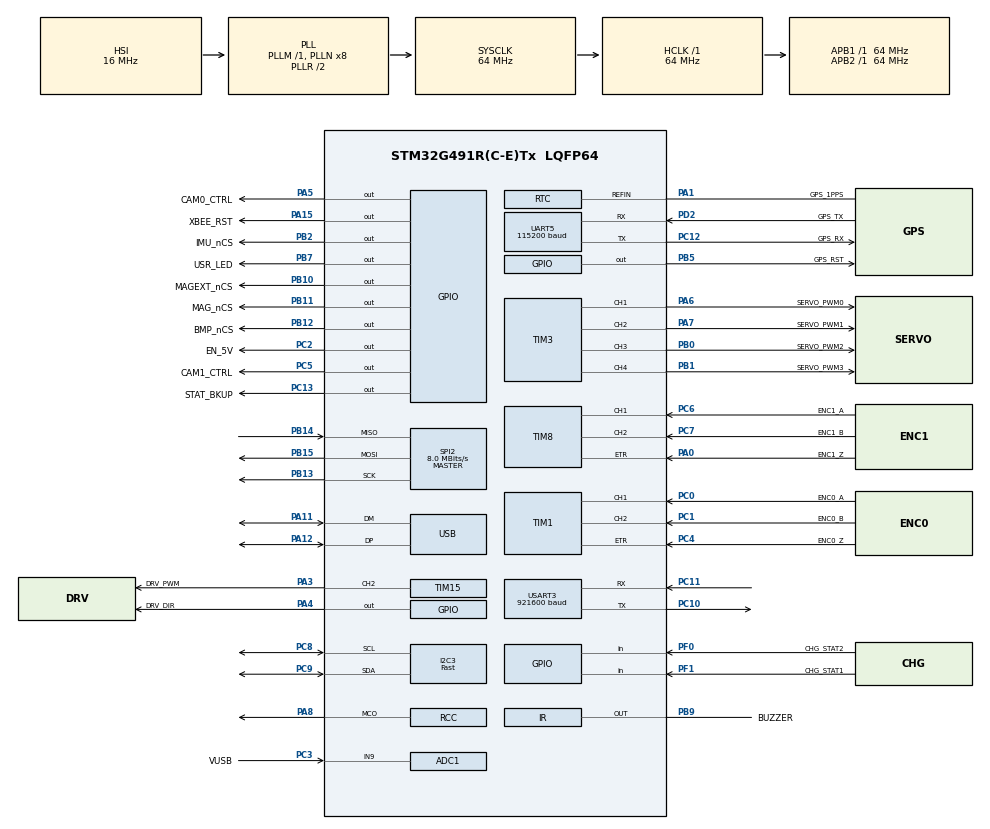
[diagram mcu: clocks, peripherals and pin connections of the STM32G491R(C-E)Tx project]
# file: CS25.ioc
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ADC1.Channel-1\#ChannelRegularConversion=ADC_CHANNEL_9
ADC1.NbrOfConversionFlag=1
ADC1.OffsetNumber-1\#ChannelRegularConversion=ADC_OFFSET_NONE
ADC1.Rank-1\#ChannelRegularConversion=1
ADC1.SamplingTime-1\#ChannelRegularConversion=ADC_SAMPLETIME_2CYCLES_5
ADC1.master=1
Dma.Request0=UART5_RX
Dma.Request1=USART3_RX
Dma.UART5_RX.0.Direction=DMA_PERIPH_TO_MEMORY
Dma.UART5_RX.0.EventEnable=DISABLE
Dma.UART5_RX.0.Instance=DMA1_Channel1
Dma.UART5_RX.0.MemDataAlignment=DMA_MDATAALIGN_BYTE
Dma.UART5_RX.0.MemInc=DMA_MINC_ENABLE
Dma.UART5_RX.0.Mode=DMA_NORMAL
Dma.UART5_RX.0.PeriphDataAlignment=DMA_PDATAALIGN_BYTE
Dma.UART5_RX.0.PeriphInc=DMA_PINC_DISABLE
Dma.UART5_RX.0.Polarity=HAL_DMAMUX_REQ_GEN_RISING
Dma.UART5_RX.0.Priority=DMA_PRIORITY_VERY_HIGH
Dma.UART5_RX.0.RequestNumber=1
Dma.UART5_RX.0.SignalID=NONE
Dma.UART5_RX.0.SyncEnable=DISABLE
Dma.UART5_RX.0.SyncPolarity=HAL_DMAMUX_SYNC_NO_EVENT
Dma.UART5_RX.0.SyncRequestNumber=1
Dma.UART5_RX.0.SyncSignalID=NONE
Dma.USART3_RX.1.Direction=DMA_PERIPH_TO_MEMORY
Dma.USART3_RX.1.EventEnable=DISABLE
Dma.USART3_RX.1.Instance=DMA1_Channel2
Dma.USART3_RX.1.MemDataAlignment=DMA_MDATAALIGN_BYTE
Dma.USART3_RX.1.MemInc=DMA_MINC_ENABLE
Dma.USART3_RX.1.Mode=DMA_NORMAL
Dma.USART3_RX.1.PeriphDataAlignment=DMA_PDATAALIGN_BYTE
Dma.USART3_RX.1.PeriphInc=DMA_PINC_DISABLE
Dma.USART3_RX.1.Polarity=HAL_DMAMUX_REQ_GEN_RISING
Dma.USART3_RX.1.Priority=DMA_PRIORITY_VERY_HIGH
Dma.USART3_RX.1.RequestNumber=1
Dma.USART3_RX.1.SignalID=NONE
Dma.USART3_RX.1.SyncEnable=DISABLE
Dma.USART3_RX.1.SyncPolarity=HAL_DMAMUX_SYNC_NO_EVENT
Dma.USART3_RX.1.SyncRequestNumber=1
Dma.USART3_RX.1.SyncSignalID=NONE
FREERTOS.BinarySemaphores01=globalData,Dynamic,NULL,Available
FREERTOS.Tasks01=readSensors,0,512,StartReadSensors,Default,NULL,Dynamic,NULL,NULL;sendTelemetry,0,512,StartSendTelemetry,Default,NULL,Dynamic,NULL,NULL;readCommands,0,512,StartReadCommands,Default,NULL,Dynamic,NULL,NULL;guideNavCtrl,0,512,StartGNC,Default,NULL,Dynamic,NULL,NULL
FREERTOS.configIDLE_SHOULD_YIELD=1
FREERTOS.configMINIMAL_STACK_SIZE=512
FREERTOS.configTOTAL_HEAP_SIZE=12288
FREERTOS.configUSE_NEWLIB_REENTRANT=0
FREERTOS.configUSE_PREEMPTION=1
I2C3.I2C_Speed_Mode=I2C_Fast
I2C3.Timing=0x00C12166
Mcu.Family=STM32G4
Mcu.Name=STM32G491R(C-E)Tx
Mcu.Package=LQFP64
NVIC.DMA1_Channel1_IRQn=true\:5\:0\:false\:false\:true\:true\:false\:true\:true
NVIC.DMA1_Channel2_IRQn=true\:5\:0\:false\:false\:true\:true\:false\:true\:true
NVIC.PriorityGroup=NVIC_PRIORITYGROUP_4
NVIC.TIM6_DAC_IRQn=true\:15\:0\:false\:false\:true\:false\:false\:true\:true
NVIC.TimeBase=TIM6_DAC_IRQn
NVIC.TimeBaseIP=TIM6
NVIC.UART5_IRQn=true\:5\:0\:false\:false\:true\:true\:true\:true\:true
NVIC.USART3_IRQn=true\:14\:0\:true\:false\:true\:true\:true\:true\:true
NVIC.USB_LP_IRQn=true\:5\:0\:false\:false\:true\:true\:false\:true\:true
PA0.GPIO_Label=ENC1_Z
PA0.Signal=S_TIM8_ETR
PA1.GPIO_Label=GPS_1PPS
PA1.Mode=Reference_Clock_Detection_Activate
PA1.Signal=RTC_REFIN
PA11.Mode=Device
PA11.Signal=USB_DM
PA12.Mode=Device
PA12.Signal=USB_DP
PA13.GPIO_Label=SWDIO
PA13.Mode=Trace_Asynchronous_SW
PA13.Signal=SYS_JTMS-SWDIO
PA14.GPIO_Label=SWCLK
PA14.Mode=Trace_Asynchronous_SW
PA14.Signal=SYS_JTCK-SWCLK
PA15.GPIO_Label=XBEE_RST
PA15.Signal=GPIO_Output
PA2.GPIO_Label=CLK_32K
PA2.Mode=Clock-out-LSCO
PA2.Signal=RCC_LSCO
PA3.GPIO_Label=DRV_PWM
PA3.Signal=S_TIM15_CH2
PA4.GPIO_Label=DRV_DIR
PA4.Signal=GPIO_Output
PA5.GPIO_Label=CAM0_CTRL
PA5.Signal=GPIO_Output
PA6.GPIO_Label=SERVO_PWM0
PA6.Signal=S_TIM3_CH1
PA7.GPIO_Label=SERVO_PWM1
PA7.Signal=S_TIM3_CH2
PA8.Mode=Clock-out
PA8.Signal=RCC_MCO
PB0.GPIO_Label=SERVO_PWM2
PB0.Signal=S_TIM3_CH3
PB1.GPIO_Label=SERVO_PWM3
PB1.Signal=S_TIM3_CH4
PB10.GPIO_Label=MAGEXT_nCS
PB10.Signal=GPIO_Output
PB11.GPIO_Label=MAG_nCS
PB11.Signal=GPIO_Output
PB12.GPIO_Label=BMP_nCS
PB12.Signal=GPIO_Output
PB13.Mode=Full_Duplex_Master
PB13.Signal=SPI2_SCK
PB14.Mode=Full_Duplex_Master
PB14.Signal=SPI2_MISO
PB15.Mode=Full_Duplex_Master
PB15.Signal=SPI2_MOSI
PB2.GPIO_Label=IMU_nCS
PB2.Signal=GPIO_Output
PB3.GPIO_Label=SWO
PB3.Mode=Trace_Asynchronous_SW
PB3.Signal=SYS_JTDO-SWO
PB4.Signal=UCPD1_CC2
PB5.GPIO_Label=GPS_RST
PB5.GPIO_ModeDefaultOutputPP=GPIO_MODE_OUTPUT_OD
PB5.GPIO_PuPd=GPIO_NOPULL
PB5.Signal=GPIO_Output
PB6.Signal=UCPD1_CC1
PB7.GPIO_Label=USR_LED
PB7.Signal=GPIO_Output
PB9.GPIO_FM9=SYSCFG_FASTMODEPLUS_PB9
PB9.GPIO_Label=BUZZER
PB9.Mode=INFRARED
PB9.Signal=IR_OUT
PC0.GPIO_Label=ENC0_A
PC0.Signal=S_TIM1_CH1
PC1.GPIO_Label=ENC0_B
PC1.Signal=S_TIM1_CH2
PC10.Mode=Asynchronous
PC10.Signal=USART3_TX
PC11.Mode=Asynchronous
PC11.Signal=USART3_RX
PC12.GPIO_Label=GPS_RX
PC12.Mode=Asynchronous
PC12.Signal=UART5_TX
PC13.GPIO_Label=STAT_BKUP
PC13.Signal=GPIO_Output
PC14-OSC32_IN.GPIO_Label=OSC32_IN
PC14-OSC32_IN.Mode=LSE-External-Oscillator
PC14-OSC32_IN.Signal=RCC_OSC32_IN
PC15-OSC32_OUT.GPIO_Label=OSC32_OUT
PC15-OSC32_OUT.Mode=LSE-External-Oscillator
PC15-OSC32_OUT.Signal=RCC_OSC32_OUT
PC2.GPIO_Label=EN_5V
PC2.Signal=GPIO_Output
PC3.GPIO_Label=VUSB
PC3.Mode=IN9-Single-Ended
PC3.Signal=ADC1_IN9
PC4.GPIO_Label=ENC0_Z
PC4.Signal=S_TIM1_ETR
PC5.GPIO_Label=CAM1_CTRL
PC5.Signal=GPIO_Output
PC6.GPIO_Label=ENC1_A
PC6.Signal=S_TIM8_CH1
PC7.GPIO_Label=ENC1_B
PC7.Signal=S_TIM8_CH2
PC8.Mode=I2C
PC8.Signal=I2C3_SCL
PC9.Mode=I2C
PC9.Signal=I2C3_SDA
PD2.GPIO_Label=GPS_TX
PD2.Mode=Asynchronous
PD2.Signal=UART5_RX
PF0-OSC_IN.GPIO_Label=CHG_STAT2
PF0-OSC_IN.Signal=GPIO_Input
PF1-OSC_OUT.GPIO_Label=CHG_STAT1
PF1-OSC_OUT.Signal=GPIO_Input
ProjectManager.HeapSize=0xF00
ProjectManager.StackSize=0x600
ProjectManager.TargetToolchain=STM32CubeIDE
RCC.ADC12Freq_Value=64000000
RCC.ADC345Freq_Value=64000000
RCC.AHBFreq_Value=64000000
RCC.APB1Freq_Value=64000000
RCC.APB1TimFreq_Value=64000000
RCC.APB2Freq_Value=64000000
RCC.APB2TimFreq_Value=64000000
RCC.CortexFreq_Value=64000000
RCC.EXTERNAL_CLOCK_VALUE=12288000
RCC.HCLKFreq_Value=64000000
RCC.HSE_VALUE=8000000
RCC.HSI48_VALUE=48000000
RCC.HSI_VALUE=16000000
RCC.LSCOSource1=RCC_LSCOSOURCE_LSE
RCC.SYSCLKFreq_VALUE=64000000
RCC.SYSCLKSource=RCC_SYSCLKSOURCE_PLLCLK
RCC.USBFreq_Value=48000000
RCC.VCOOutputFreq_Value=128000000
SH.S_TIM15_CH2.0=TIM15_CH2,PWM Generation2 CH2
SH.S_TIM1_CH1.0=TIM1_CH1,Encoder_Interface_w_index
SH.S_TIM1_CH2.0=TIM1_CH2,Encoder_Interface_w_index
SH.S_TIM1_ETR.0=TIM1_ETR,Encoder_Interface_w_index
SH.S_TIM3_CH1.0=TIM3_CH1,PWM Generation1 CH1
SH.S_TIM3_CH2.0=TIM3_CH2,PWM Generation2 CH2
SH.S_TIM3_CH3.0=TIM3_CH3,PWM Generation3 CH3
SH.S_TIM3_CH4.0=TIM3_CH4,PWM Generation4 CH4
SH.S_TIM8_CH1.0=TIM8_CH1,Encoder_Interface_w_index
SH.S_TIM8_CH2.0=TIM8_CH2,Encoder_Interface_w_index
SH.S_TIM8_ETR.0=TIM8_ETR,Encoder_Interface_w_index
SPI2.BaudRatePrescaler=SPI_BAUDRATEPRESCALER_8
SPI2.CalculateBaudRate=8.0 MBits/s
SPI2.DataSize=SPI_DATASIZE_8BIT
SPI2.Direction=SPI_DIRECTION_2LINES
SPI2.Mode=SPI_MODE_MASTER
SPI2.VirtualType=VM_MASTER
TIM15.Channel-PWM\ Generation2\ CH2=TIM_CHANNEL_2
TIM16.Channel=TIM_CHANNEL_1
TIM17.Channel=TIM_CHANNEL_1
TIM3.Channel-PWM\ Generation1\ CH1=TIM_CHANNEL_1
TIM3.Channel-PWM\ Generation2\ CH2=TIM_CHANNEL_2
TIM3.Channel-PWM\ Generation3\ CH3=TIM_CHANNEL_3
TIM3.Channel-PWM\ Generation4\ CH4=TIM_CHANNEL_4
UART5.AutoBaudRateEnableParam=UART_ADVFEATURE_AUTOBAUDRATE_DISABLE
UART5.BaudRate=115200
UART5.FIFOMode=FIFOMODE_DISABLE
UART5.MSBFirstParam=UART_ADVFEATURE_MSBFIRST_DISABLE
USART3.BaudRate=921600
USART3.VirtualMode-Asynchronous=VM_ASYNC
USB.battery_charging_enable=ENABLE
USB_DEVICE.CLASS_NAME_FS=DFU
USB_DEVICE.VirtualMode=Dfu
USB_DEVICE.VirtualModeFS=Dfu_FS
USB_Device.BSP.number=1
USB_Device0.BSP.STBoard=false
USB_Device0.BSP.api=Unknown
USB_Device0.BSP.condition=SEM_BCD_ENABLED
USB_Device0.BSP.instance=PF1-OSC_OUT
USB_Device0.BSP.ip=GPIO
USB_Device0.BSP.mode=Input
USB_Device0.BSP.name=BCD Detection
USB_Device0.BSP.solution=PF1-OSC_OUT
VP_ADC1_TempSens_Input.Mode=IN-TempSens
VP_ADC1_Vbat_Input.Mode=IN-Vbat
VP_ADC1_Vref_Input.Mode=IN-Vrefint
VP_CORDIC_VS_CORDIC.Mode=CORDIC_Activate
VP_FMAC_VS_FMAC.Mode=FMAC_Activate
VP_FREERTOS_VS_CMSIS_V1.Mode=CMSIS_V1
VP_RCC_VS_LSE.Mode=CRS SYNC Source LSE
VP_RNG_VS_RNG.Mode=RNG_Activate
VP_RTC_VS_RTC_Activate.Mode=RTC_Enabled
VP_SYS_VS_DBSignals.Mode=DisableDeadBatterySignals
VP_SYS_VS_tim6.Mode=TIM6
VP_SYS_V_PVD_IN.Mode=Mode_PVD_Int
VP_SYS_V_VREFBUF.Mode=ExternalMode
VP_TIM16_VS_ClockSourceINT.Mode=Enable_Timer
VP_TIM16_VS_no_output1.Mode=PWM Generation1 No Output
VP_TIM17_VS_ClockSourceINT.Mode=Enable_Timer
VP_TIM17_VS_no_output1.Mode=PWM Generation1 No Output
VP_TIM3_VS_ClockSourceINT.Mode=Internal
VP_USB_DEVICE_VS_USB_DEVICE_DFU_FS.Mode=DFU_FS
board=custom

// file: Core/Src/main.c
/* USER CODE BEGIN Header */
/**
 ******************************************************************************
 * @file           : main.c
 * @brief          : Main program body
 ******************************************************************************
 * @attention
 *
 * Copyright (c) 2025 STMicroelectronics.
 * All rights reserved.
 *
 * This software is licensed under terms that can be found in the LICENSE file
 * in the root directory of this software component.
 * If no LICENSE file comes with this software, it is provided AS-IS.
 *
 ******************************************************************************
 */
/* USER CODE END Header */
#include "main.h"
#include "cmsis_os.h"
#include "usb_device.h"

/* USER CODE BEGIN Includes */
#include "global.h"
//#include "commands.h"
#include "uart_interrupt.h"

#include "../../Drivers/ICM42688P/ICM42688PSPI.h"
#include "../../Drivers/MS5607/MS5607SPI.h"
#include "../../Drivers/BMM150/BMM150SPI.h"
#include "../../Drivers/LC76G/LC76G.h"
#include "../../Drivers/AMT10E2/AMT10E2.h"
#include "../../Drivers/BQ28Z610/BQ28Z610I2C.h"
#include "../../Drivers/DRV8838/DRV8838.h"

/* USER CODE END Includes */

/* USER CODE BEGIN PD */

#define BUFFER_SIZE 128
#define XBEE_MAX_PAYLOAD 80   // Safe value

/* USER CODE END PD */

/* USER CODE BEGIN PM */
int _write(int fd, char *ptr, int len)
{
  // ignore fd, just send to UART3
  HAL_UART_Transmit(&huart3, (uint8_t *)ptr, len, HAL_MAX_DELAY);
  return len;
}

void _enable_led() {
	HAL_GPIO_WritePin(USR_LED_GPIO_Port, USR_LED_Pin, GPIO_PIN_RESET);
	return;
}

void _disable_led() {
	HAL_GPIO_WritePin(USR_LED_GPIO_Port, USR_LED_Pin, GPIO_PIN_SET);
	return;
}
/* USER CODE END PM */

ADC_HandleTypeDef hadc1;

CORDIC_HandleTypeDef hcordic;

FMAC_HandleTypeDef hfmac;

I2C_HandleTypeDef hi2c3;

RNG_HandleTypeDef hrng;

RTC_HandleTypeDef hrtc;

SPI_HandleTypeDef hspi2;

TIM_HandleTypeDef htim1;
TIM_HandleTypeDef htim3;
TIM_HandleTypeDef htim8;
TIM_HandleTypeDef htim15;
TIM_HandleTypeDef htim16;
TIM_HandleTypeDef htim17;

UART_HandleTypeDef huart5;
UART_HandleTypeDef huart3;
DMA_HandleTypeDef hdma_uart5_rx;
DMA_HandleTypeDef hdma_usart3_rx;

osThreadId readSensorsHandle;
osThreadId sendTelemetryHandle;
osThreadId readCommandsHandle;
osThreadId guideNavCtrlHandle;
osSemaphoreId globalDataHandle;
/* USER CODE BEGIN PV */

uint8_t dma_buffer[BUFFER_SIZE]   = { 0 };
char transmit_buffer[BUFFER_SIZE] = { 0 };
char receive_buffer[BUFFER_SIZE]  = { 0 };
char command_buffer[BUFFER_SIZE]  = { 0 };

// Flags for GPS and XBEE since they use UART DMA
volatile uint16_t GPS_SIZE 	   = 0;
volatile uint8_t GPS_READY 	   = 0;
volatile uint16_t COMMAND_SIZE = 0;
volatile uint8_t COMMAND_READY = 0;

/* USER CODE END PV */

void SystemClock_Config(void);
static void MX_GPIO_Init(void);
static void MX_DMA_Init(void);
static void MX_ADC1_Init(void);
static void MX_I2C3_Init(void);
static void MX_IRTIM_Init(void);
static void MX_RTC_Init(void);
static void MX_SPI2_Init(void);
static void MX_TIM1_Init(void);
static void MX_TIM3_Init(void);
static void MX_TIM8_Init(void);
static void MX_TIM15_Init(void);
static void MX_TIM16_Init(void);
static void MX_TIM17_Init(void);
static void MX_UART5_Init(void);
static void MX_RNG_Init(void);
static void MX_USART3_UART_Init(void);
static void MX_CORDIC_Init(void);
static void MX_FMAC_Init(void);
void StartReadSensors(void const * argument);
void StartSendTelemetry(void const * argument);
void StartReadCommands(void const * argument);
void StartGNC(void const * argument);

/* USER CODE BEGIN 0 */

void HAL_UARTEx_RxEventCallback(UART_HandleTypeDef *huart, uint16_t size)
{
  if (huart->Instance == UART5)
  {
    if (!GPS_READY)
    {
		GPS_SIZE = size;
		GPS_READY = 1;
		memcpy(receive_buffer, dma_buffer, size);
    }
  }
  else if (huart->Instance == USART3)
  {
    if (!COMMAND_READY)
    {
		COMMAND_SIZE = size;
		COMMAND_READY = 1;
		memcpy(command_buffer, dma_buffer, size);
    }
  }
  else
  {
    // FIXME : Change this for a DBG LED in the new code
	  HAL_GPIO_WritePin(USR_LED_GPIO_Port, USR_LED_Pin, GPIO_PIN_RESET);
  }

  HAL_UARTEx_ReceiveToIdle_DMA(huart, dma_buffer, BUFFER_SIZE);
  __HAL_DMA_DISABLE_IT(huart->hdmarx, DMA_IT_HT);
}

void HAL_UARTEx_ErrorCallback(UART_HandleTypeDef *huart) {
	while(1) {
		// 1 quick 2 slow to show a UART error
		HAL_GPIO_WritePin(USR_LED_GPIO_Port, USR_LED_Pin, GPIO_PIN_RESET);
		HAL_Delay(100);
		HAL_GPIO_WritePin(USR_LED_GPIO_Port, USR_LED_Pin, GPIO_PIN_RESET);
		HAL_Delay(100);
		HAL_GPIO_WritePin(USR_LED_GPIO_Port, USR_LED_Pin, GPIO_PIN_RESET);
		HAL_Delay(200);
		HAL_GPIO_WritePin(USR_LED_GPIO_Port, USR_LED_Pin, GPIO_PIN_RESET);
		HAL_Delay(200);
		HAL_GPIO_WritePin(USR_LED_GPIO_Port, USR_LED_Pin, GPIO_PIN_RESET);
		HAL_Delay(200);
		HAL_GPIO_WritePin(USR_LED_GPIO_Port, USR_LED_Pin, GPIO_PIN_RESET);
		HAL_Delay(200);
	}
}

/* USER CODE END 0 */

int main(void)
{

  /* MCU Configuration--------------------------------------------------------*/

  /* Reset of all peripherals, Initializes the Flash interface and the Systick. */
  HAL_Init();

  /* Configure the system clock */
  SystemClock_Config();

  /* Initialize all configured peripherals */
  MX_GPIO_Init();
  MX_DMA_Init();
  MX_ADC1_Init();
  MX_I2C3_Init();
  MX_IRTIM_Init();
  MX_RTC_Init();
  MX_SPI2_Init();
  MX_TIM1_Init();
  MX_TIM3_Init();
  MX_TIM8_Init();
  MX_TIM15_Init();
  MX_TIM16_Init();
  MX_TIM17_Init();
  MX_UART5_Init();
  MX_RNG_Init();
  MX_USART3_UART_Init();
  MX_CORDIC_Init();
  MX_FMAC_Init();
  /* USER CODE BEGIN 2 */
  // Feedback LED
  HAL_GPIO_WritePin(USR_LED_GPIO_Port, USR_LED_Pin, GPIO_PIN_SET);

  // Disable ALL chip selects
  HAL_GPIO_WritePin(IMU_nCS_GPIO_Port, IMU_nCS_Pin, GPIO_PIN_SET);
  HAL_GPIO_WritePin(BMP_nCS_GPIO_Port, BMP_nCS_Pin, GPIO_PIN_SET);
  HAL_GPIO_WritePin(MAG_nCS_GPIO_Port, MAG_nCS_Pin, GPIO_PIN_SET);
  HAL_GPIO_WritePin(MAGEXT_nCS_GPIO_Port, MAGEXT_nCS_Pin, GPIO_PIN_SET);

  // Enable XBEE
  HAL_GPIO_WritePin(XBEE_RST_GPIO_Port, XBEE_RST_Pin, GPIO_PIN_SET);
  HAL_Delay(500);

  // Change AP mode from AT to API w/out Escapes ---------------------------------------
//  HAL_UART_Transmit(&huart3, "+++", 3, HAL_MAX_DELAY);
//  char OK_buff[3];
//  HAL_UART_Receive(&huart3, OK_buff, 3, 5000);
//
//  if (strncmp(OK_buff, "OK", 2) != 0) {
//    if (strncmp(OK_buff, "ER", 2) == 0) {
//  	  HAL_GPIO_WritePin(USR_LED_GPIO_Port, USR_LED_Pin, GPIO_PIN_RESET);
//  	  while(1);
//  	}
//
//  	while(1) {
//	  HAL_GPIO_WritePin(USR_LED_GPIO_Port, USR_LED_Pin, GPIO_PIN_RESET);
//	  HAL_Delay(400);
//	  HAL_GPIO_WritePin(USR_LED_GPIO_Port, USR_LED_Pin, GPIO_PIN_SET);
//	  HAL_Delay(100);
//	  HAL_GPIO_WritePin(USR_LED_GPIO_Port, USR_LED_Pin, GPIO_PIN_RESET);
//      HAL_Delay(200);
//	  HAL_GPIO_WritePin(USR_LED_GPIO_Port, USR_LED_Pin, GPIO_PIN_SET);
//	  HAL_Delay(100);
//  	}
//  }
////  HAL_Delay(1000);
//
//  HAL_UART_Transmit(&huart3, "ATAP 1\r", 7, HAL_MAX_DELAY);
//  HAL_Delay(1000);
//  HAL_UART_Transmit(&huart3, "ATAC\r", 5, HAL_MAX_DELAY);
//  HAL_Delay(1000);
//  HAL_UART_Transmit(&huart3, "ATWR\r", 5, HAL_MAX_DELAY);
//  HAL_Delay(1000);
//  HAL_UART_Transmit(&huart3, "ATCN\r", 5, HAL_MAX_DELAY);
//  HAL_Delay(100);
  // -----------------------------------------------------------------------------------

  // Ensure ID parameter matches Team ID
  uint8_t ATID[10] = {0x7E, 0x00, 0x06, 0x08, 0x01, 0x49, 0x44, 0x31, 0x74, 0xC4};
  uint8_t resp[9];
  HAL_UART_Transmit(&huart3, ATID, sizeof(ATID), HAL_MAX_DELAY);
  HAL_UART_Receive(&huart3, resp, sizeof(resp), 5000);
  if (resp[0] != 0x7E || resp[8] != 0xE9) {
	  	  HAL_GPIO_WritePin(USR_LED_GPIO_Port, USR_LED_Pin, GPIO_PIN_RESET);
	  	  HAL_Delay(400);
	  	  HAL_GPIO_WritePin(USR_LED_GPIO_Port, USR_LED_Pin, GPIO_PIN_SET);
	  	  HAL_Delay(100);
	  	  HAL_GPIO_WritePin(USR_LED_GPIO_Port, USR_LED_Pin, GPIO_PIN_RESET);
	        HAL_Delay(200);
	  	  HAL_GPIO_WritePin(USR_LED_GPIO_Port, USR_LED_Pin, GPIO_PIN_SET);
	  	  HAL_Delay(100);
  }
  HAL_Delay(1000);

  // Hold GPS in reset (LOW)
  HAL_GPIO_WritePin(GPS_RST_GPIO_Port, GPS_RST_Pin, GPIO_PIN_RESET);
  HAL_Delay(100);

  // Fully reset UART5 peripheral
  __HAL_RCC_UART5_FORCE_RESET();
  __HAL_RCC_UART5_RELEASE_RESET();
  MX_UART5_Init();   // reinitialize UART

  // Clear all flags
  __HAL_UART_CLEAR_OREFLAG(&huart5);
  __HAL_UART_CLEAR_FEFLAG(&huart5);
  __HAL_UART_CLEAR_NEFLAG(&huart5);
  __HAL_UART_CLEAR_PEFLAG(&huart5);

  // Fully reset UART3 peripheral
  __HAL_RCC_USART3_FORCE_RESET();
  __HAL_RCC_USART3_RELEASE_RESET();
  MX_USART3_UART_Init();   // reinitialize UART

  // Clear all flags
  __HAL_UART_CLEAR_OREFLAG(&huart3);
  __HAL_UART_CLEAR_FEFLAG(&huart3);
  __HAL_UART_CLEAR_NEFLAG(&huart3);
  __HAL_UART_CLEAR_PEFLAG(&huart3);

  // Now release GPS reset
  HAL_GPIO_WritePin(GPS_RST_GPIO_Port, GPS_RST_Pin, GPIO_PIN_SET);
  HAL_Delay(5000);

  // Initialize IMU
  ICM42688P_init(&hspi2, IMU_nCS_GPIO_Port, IMU_nCS_Pin);

  // Initialize MS5607
  MS5607_Init(&hspi2, BMP_nCS_GPIO_Port, BMP_nCS_Pin);

  // Initialize BMM150
  struct bmm150_dev bmm150 = BMM150_spi_init(&hspi2, MAG_nCS_GPIO_Port, MAG_nCS_Pin);

  // Initialize LC76G
  LC76G_init(&huart5);

  // Initializing AMT10E2
  QENC_Init_Encoder0();

  //drv8838_init(&htim15, DRV_DIR_GPIO_Port, DRV_DIR_Pin);

  init_mission_data();

  // Flash LED to signal INITs are done
  HAL_GPIO_WritePin(USR_LED_GPIO_Port, USR_LED_Pin, GPIO_PIN_RESET);
  HAL_Delay(500);
  HAL_GPIO_WritePin(USR_LED_GPIO_Port, USR_LED_Pin, GPIO_PIN_SET);
  HAL_Delay(200);

  // UART 5
  // Check if ORE flag is set, which can happen if data is present on UART RX line
  if (__HAL_UART_GET_FLAG(&huart5, UART_FLAG_ORE)) {
    __HAL_UART_CLEAR_FLAG(&huart5, UART_CLEAR_OREF);
  }
  // receive until idle, then trigger interrupt
  HAL_UARTEx_ReceiveToIdle_DMA(&huart5, dma_buffer, BUFFER_SIZE); // receive until idle, then trigger interrupt
  __HAL_DMA_DISABLE_IT(huart5.hdmarx, DMA_IT_HT); // Disables "Half Transfer" interrupt

  // USART 3
  // Check if ORE flag is set, which can happen if data is present on UART RX line
  if (__HAL_UART_GET_FLAG(&huart3, UART_FLAG_ORE)) {
    __HAL_UART_CLEAR_FLAG(&huart3, UART_CLEAR_OREF);
  }
  // receive until idle, then trigger interrupt
  HAL_UARTEx_ReceiveToIdle_DMA(&huart3, dma_buffer, BUFFER_SIZE); // receive until idle, then trigger interrupt
  __HAL_DMA_DISABLE_IT(huart3.hdmarx, DMA_IT_HT); // Disables "Half Transfer" interrupt

  /* USER CODE END 2 */

  /* Create the semaphores(s) */
  /* definition and creation of globalData */
  osSemaphoreDef(globalData);
  globalDataHandle = osSemaphoreCreate(osSemaphore(globalData), 1);

  /* Create the thread(s) */
  /* definition and creation of readSensors */
  osThreadDef(readSensors, StartReadSensors, osPriorityNormal, 0, 512);
  readSensorsHandle = osThreadCreate(osThread(readSensors), NULL);

  /* definition and creation of sendTelemetry */
  osThreadDef(sendTelemetry, StartSendTelemetry, osPriorityNormal, 0, 512);
  sendTelemetryHandle = osThreadCreate(osThread(sendTelemetry), NULL);

  /* definition and creation of readCommands */
  osThreadDef(readCommands, StartReadCommands, osPriorityNormal, 0, 512);
  readCommandsHandle = osThreadCreate(osThread(readCommands), NULL);

  /* definition and creation of guideNavCtrl */
  osThreadDef(guideNavCtrl, StartGNC, osPriorityNormal, 0, 512);
  guideNavCtrlHandle = osThreadCreate(osThread(guideNavCtrl), NULL);

  /* Start scheduler */
  osKernelStart();

  /* We should never get here as control is now taken by the scheduler */

  /* Infinite loop */
  while (1)
  {
	  HAL_GPIO_TogglePin(USR_LED_GPIO_Port, USR_LED_Pin);
	  HAL_Delay(100);
  }
}

void SystemClock_Config(void)
{
  RCC_OscInitTypeDef RCC_OscInitStruct = {0};
  RCC_ClkInitTypeDef RCC_ClkInitStruct = {0};
  RCC_CRSInitTypeDef pInit = {0};

  /** Configure the main internal regulator output voltage
  */
  HAL_PWREx_ControlVoltageScaling(PWR_REGULATOR_VOLTAGE_SCALE1);

  /** Configure LSE Drive Capability
  */
  HAL_PWR_EnableBkUpAccess();
  __HAL_RCC_LSEDRIVE_CONFIG(RCC_LSEDRIVE_LOW);

  /** Initializes the RCC Oscillators according to the specified parameters
  * in the RCC_OscInitTypeDef structure.
  */
  RCC_OscInitStruct.OscillatorType = RCC_OSCILLATORTYPE_HSI|RCC_OSCILLATORTYPE_HSI48
                              |RCC_OSCILLATORTYPE_LSI|RCC_OSCILLATORTYPE_LSE;
  RCC_OscInitStruct.LSEState = RCC_LSE_ON;
  RCC_OscInitStruct.HSIState = RCC_HSI_ON;
  RCC_OscInitStruct.HSICalibrationValue = RCC_HSICALIBRATION_DEFAULT;
  RCC_OscInitStruct.LSIState = RCC_LSI_ON;
  RCC_OscInitStruct.HSI48State = RCC_HSI48_ON;
  RCC_OscInitStruct.PLL.PLLState = RCC_PLL_ON;
  RCC_OscInitStruct.PLL.PLLSource = RCC_PLLSOURCE_HSI;
  RCC_OscInitStruct.PLL.PLLM = RCC_PLLM_DIV1;
  RCC_OscInitStruct.PLL.PLLN = 8;
  RCC_OscInitStruct.PLL.PLLP = RCC_PLLP_DIV2;
  RCC_OscInitStruct.PLL.PLLQ = RCC_PLLQ_DIV2;
  RCC_OscInitStruct.PLL.PLLR = RCC_PLLR_DIV2;
  if (HAL_RCC_OscConfig(&RCC_OscInitStruct) != HAL_OK)
  {
    Error_Handler();
  }

  /** Initializes the CPU, AHB and APB buses clocks
  */
  RCC_ClkInitStruct.ClockType = RCC_CLOCKTYPE_HCLK|RCC_CLOCKTYPE_SYSCLK
                              |RCC_CLOCKTYPE_PCLK1|RCC_CLOCKTYPE_PCLK2;
  RCC_ClkInitStruct.SYSCLKSource = RCC_SYSCLKSOURCE_PLLCLK;
  RCC_ClkInitStruct.AHBCLKDivider = RCC_SYSCLK_DIV1;
  RCC_ClkInitStruct.APB1CLKDivider = RCC_HCLK_DIV1;
  RCC_ClkInitStruct.APB2CLKDivider = RCC_HCLK_DIV1;

  if (HAL_RCC_ClockConfig(&RCC_ClkInitStruct, FLASH_LATENCY_2) != HAL_OK)
  {
    Error_Handler();
  }
  HAL_RCC_MCOConfig(RCC_MCO1, RCC_MCO1SOURCE_HSI, RCC_MCODIV_1);
  HAL_RCCEx_EnableLSCO(RCC_LSCOSOURCE_LSE);

  /** Enable the SYSCFG APB clock
  */
  __HAL_RCC_CRS_CLK_ENABLE();

  /** Configures CRS
  */
  pInit.Prescaler = RCC_CRS_SYNC_DIV1;
  pInit.Source = RCC_CRS_SYNC_SOURCE_LSE;
  pInit.Polarity = RCC_CRS_SYNC_POLARITY_RISING;
  pInit.ReloadValue = __HAL_RCC_CRS_RELOADVALUE_CALCULATE(48000000,32768);
  pInit.ErrorLimitValue = 34;
  pInit.HSI48CalibrationValue = 32;

  HAL_RCCEx_CRSConfig(&pInit);
}

static void MX_ADC1_Init(void)
{

  ADC_MultiModeTypeDef multimode = {0};
  ADC_ChannelConfTypeDef sConfig = {0};

  /** Common config
  */
  hadc1.Instance = ADC1;
  hadc1.Init.ClockPrescaler = ADC_CLOCK_SYNC_PCLK_DIV2;
  hadc1.Init.Resolution = ADC_RESOLUTION_12B;
  hadc1.Init.DataAlign = ADC_DATAALIGN_RIGHT;
  hadc1.Init.GainCompensation = 0;
  hadc1.Init.ScanConvMode = ADC_SCAN_DISABLE;
  hadc1.Init.EOCSelection = ADC_EOC_SINGLE_CONV;
  hadc1.Init.LowPowerAutoWait = DISABLE;
  hadc1.Init.ContinuousConvMode = DISABLE;
  hadc1.Init.NbrOfConversion = 1;
  hadc1.Init.DiscontinuousConvMode = DISABLE;
  hadc1.Init.ExternalTrigConv = ADC_SOFTWARE_START;
  hadc1.Init.ExternalTrigConvEdge = ADC_EXTERNALTRIGCONVEDGE_NONE;
  hadc1.Init.DMAContinuousRequests = DISABLE;
  hadc1.Init.Overrun = ADC_OVR_DATA_PRESERVED;
  hadc1.Init.OversamplingMode = DISABLE;
  if (HAL_ADC_Init(&hadc1) != HAL_OK)
  {
    Error_Handler();
  }

  /** Configure the ADC multi-mode
  */
  multimode.Mode = ADC_MODE_INDEPENDENT;
  if (HAL_ADCEx_MultiModeConfigChannel(&hadc1, &multimode) != HAL_OK)
  {
    Error_Handler();
  }

  /** Configure Regular Channel
  */
  sConfig.Channel = ADC_CHANNEL_9;
  sConfig.Rank = ADC_REGULAR_RANK_1;
  sConfig.SamplingTime = ADC_SAMPLETIME_2CYCLES_5;
  sConfig.SingleDiff = ADC_SINGLE_ENDED;
  sConfig.OffsetNumber = ADC_OFFSET_NONE;
  sConfig.Offset = 0;
  if (HAL_ADC_ConfigChannel(&hadc1, &sConfig) != HAL_OK)
  {
    Error_Handler();
  }

}

static void MX_CORDIC_Init(void)
{

  hcordic.Instance = CORDIC;
  if (HAL_CORDIC_Init(&hcordic) != HAL_OK)
  {
    Error_Handler();
  }

}

static void MX_FMAC_Init(void)
{

  hfmac.Instance = FMAC;
  if (HAL_FMAC_Init(&hfmac) != HAL_OK)
  {
    Error_Handler();
  }

}

static void MX_I2C3_Init(void)
{

  hi2c3.Instance = I2C3;
  hi2c3.Init.Timing = 0x00C12166;
  hi2c3.Init.OwnAddress1 = 0;
  hi2c3.Init.AddressingMode = I2C_ADDRESSINGMODE_7BIT;
  hi2c3.Init.DualAddressMode = I2C_DUALADDRESS_DISABLE;
  hi2c3.Init.OwnAddress2 = 0;
  hi2c3.Init.OwnAddress2Masks = I2C_OA2_NOMASK;
  hi2c3.Init.GeneralCallMode = I2C_GENERALCALL_DISABLE;
  hi2c3.Init.NoStretchMode = I2C_NOSTRETCH_DISABLE;
  if (HAL_I2C_Init(&hi2c3) != HAL_OK)
  {
    Error_Handler();
  }

  /** Configure Analogue filter
  */
  if (HAL_I2CEx_ConfigAnalogFilter(&hi2c3, I2C_ANALOGFILTER_ENABLE) != HAL_OK)
  {
    Error_Handler();
  }

  /** Configure Digital filter
  */
  if (HAL_I2CEx_ConfigDigitalFilter(&hi2c3, 0) != HAL_OK)
  {
    Error_Handler();
  }

}

static void MX_IRTIM_Init(void)
{

}

static void MX_RNG_Init(void)
{

  hrng.Instance = RNG;
  hrng.Init.ClockErrorDetection = RNG_CED_ENABLE;
  if (HAL_RNG_Init(&hrng) != HAL_OK)
  {
    Error_Handler();
  }

}

static void MX_RTC_Init(void)
{

  /** Initialize RTC Only
  */
  hrtc.Instance = RTC;
  hrtc.Init.HourFormat = RTC_HOURFORMAT_24;
  hrtc.Init.AsynchPrediv = 127;
  hrtc.Init.SynchPrediv = 255;
  hrtc.Init.OutPut = RTC_OUTPUT_DISABLE;
  hrtc.Init.OutPutRemap = RTC_OUTPUT_REMAP_NONE;
  hrtc.Init.OutPutPolarity = RTC_OUTPUT_POLARITY_HIGH;
  hrtc.Init.OutPutType = RTC_OUTPUT_TYPE_OPENDRAIN;
  hrtc.Init.OutPutPullUp = RTC_OUTPUT_PULLUP_NONE;
  if (HAL_RTC_Init(&hrtc) != HAL_OK)
  {
    Error_Handler();
  }

  /** Enable the reference Clock input
  */
  if (HAL_RTCEx_SetRefClock(&hrtc) != HAL_OK)
  {
    Error_Handler();
  }

}

static void MX_SPI2_Init(void)
{

  /* SPI2 parameter configuration*/
  hspi2.Instance = SPI2;
  hspi2.Init.Mode = SPI_MODE_MASTER;
  hspi2.Init.Direction = SPI_DIRECTION_2LINES;
  hspi2.Init.DataSize = SPI_DATASIZE_8BIT;
  hspi2.Init.CLKPolarity = SPI_POLARITY_LOW;
  hspi2.Init.CLKPhase = SPI_PHASE_1EDGE;
  hspi2.Init.NSS = SPI_NSS_SOFT;
  hspi2.Init.BaudRatePrescaler = SPI_BAUDRATEPRESCALER_8;
  hspi2.Init.FirstBit = SPI_FIRSTBIT_MSB;
  hspi2.Init.TIMode = SPI_TIMODE_DISABLE;
  hspi2.Init.CRCCalculation = SPI_CRCCALCULATION_DISABLE;
  hspi2.Init.CRCPolynomial = 7;
  hspi2.Init.CRCLength = SPI_CRC_LENGTH_DATASIZE;
  hspi2.Init.NSSPMode = SPI_NSS_PULSE_ENABLE;
  if (HAL_SPI_Init(&hspi2) != HAL_OK)
  {
    Error_Handler();
  }

}

static void MX_TIM1_Init(void)
{

  TIM_Encoder_InitTypeDef sConfig = {0};
  TIM_MasterConfigTypeDef sMasterConfig = {0};
  TIMEx_EncoderIndexConfigTypeDef sEncoderIndexConfig = {0};

  htim1.Instance = TIM1;
  htim1.Init.Prescaler = 0;
  htim1.Init.CounterMode = TIM_COUNTERMODE_UP;
  htim1.Init.Period = 65535;
  htim1.Init.ClockDivision = TIM_CLOCKDIVISION_DIV1;
  htim1.Init.RepetitionCounter = 0;
  htim1.Init.AutoReloadPreload = TIM_AUTORELOAD_PRELOAD_DISABLE;
  sConfig.EncoderMode = TIM_ENCODERMODE_TI1;
  sConfig.IC1Polarity = TIM_ICPOLARITY_RISING;
  sConfig.IC1Selection = TIM_ICSELECTION_DIRECTTI;
  sConfig.IC1Prescaler = TIM_ICPSC_DIV1;
  sConfig.IC1Filter = 0;
  sConfig.IC2Polarity = TIM_ICPOLARITY_RISING;
  sConfig.IC2Selection = TIM_ICSELECTION_DIRECTTI;
  sConfig.IC2Prescaler = TIM_ICPSC_DIV1;
  sConfig.IC2Filter = 0;
  if (HAL_TIM_Encoder_Init(&htim1, &sConfig) != HAL_OK)
  {
    Error_Handler();
  }
  sMasterConfig.MasterOutputTrigger = TIM_TRGO_RESET;
  sMasterConfig.MasterOutputTrigger2 = TIM_TRGO2_RESET;
  sMasterConfig.MasterSlaveMode = TIM_MASTERSLAVEMODE_DISABLE;
  if (HAL_TIMEx_MasterConfigSynchronization(&htim1, &sMasterConfig) != HAL_OK)
  {
    Error_Handler();
  }
  sEncoderIndexConfig.Polarity = TIM_ENCODERINDEX_POLARITY_NONINVERTED;
  sEncoderIndexConfig.Prescaler = TIM_ENCODERINDEX_PRESCALER_DIV1;
  sEncoderIndexConfig.Filter = 0;
  sEncoderIndexConfig.FirstIndexEnable = DISABLE;
  sEncoderIndexConfig.Position = TIM_ENCODERINDEX_POSITION_00;
  sEncoderIndexConfig.Direction = TIM_ENCODERINDEX_DIRECTION_UP_DOWN;
  if (HAL_TIMEx_ConfigEncoderIndex(&htim1, &sEncoderIndexConfig) != HAL_OK)
  {
    Error_Handler();
  }

}

static void MX_TIM3_Init(void)
{

  TIM_ClockConfigTypeDef sClockSourceConfig = {0};
  TIM_MasterConfigTypeDef sMasterConfig = {0};
  TIM_OC_InitTypeDef sConfigOC = {0};

  htim3.Instance = TIM3;
  htim3.Init.Prescaler = 0;
  htim3.Init.CounterMode = TIM_COUNTERMODE_UP;
  htim3.Init.Period = 65535;
  htim3.Init.ClockDivision = TIM_CLOCKDIVISION_DIV1;
  htim3.Init.AutoReloadPreload = TIM_AUTORELOAD_PRELOAD_DISABLE;
  if (HAL_TIM_Base_Init(&htim3) != HAL_OK)
  {
    Error_Handler();
  }
  sClockSourceConfig.ClockSource = TIM_CLOCKSOURCE_INTERNAL;
  if (HAL_TIM_ConfigClockSource(&htim3, &sClockSourceConfig) != HAL_OK)
  {
    Error_Handler();
  }
  if (HAL_TIM_PWM_Init(&htim3) != HAL_OK)
  {
    Error_Handler();
  }
  sMasterConfig.MasterOutputTrigger = TIM_TRGO_RESET;
  sMasterConfig.MasterSlaveMode = TIM_MASTERSLAVEMODE_DISABLE;
  if (HAL_TIMEx_MasterConfigSynchronization(&htim3, &sMasterConfig) != HAL_OK)
  {
    Error_Handler();
  }
  sConfigOC.OCMode = TIM_OCMODE_PWM1;
  sConfigOC.Pulse = 0;
  sConfigOC.OCPolarity = TIM_OCPOLARITY_HIGH;
  sConfigOC.OCFastMode = TIM_OCFAST_DISABLE;
  if (HAL_TIM_PWM_ConfigChannel(&htim3, &sConfigOC, TIM_CHANNEL_1) != HAL_OK)
  {
    Error_Handler();
  }
  if (HAL_TIM_PWM_ConfigChannel(&htim3, &sConfigOC, TIM_CHANNEL_2) != HAL_OK)
  {
    Error_Handler();
  }
  if (HAL_TIM_PWM_ConfigChannel(&htim3, &sConfigOC, TIM_CHANNEL_3) != HAL_OK)
  {
    Error_Handler();
  }
  if (HAL_TIM_PWM_ConfigChannel(&htim3, &sConfigOC, TIM_CHANNEL_4) != HAL_OK)
  {
    Error_Handler();
  }
  HAL_TIM_MspPostInit(&htim3);

}

static void MX_TIM8_Init(void)
{

  TIM_Encoder_InitTypeDef sConfig = {0};
  TIM_MasterConfigTypeDef sMasterConfig = {0};
  TIMEx_EncoderIndexConfigTypeDef sEncoderIndexConfig = {0};

  htim8.Instance = TIM8;
  htim8.Init.Prescaler = 0;
  htim8.Init.CounterMode = TIM_COUNTERMODE_UP;
  htim8.Init.Period = 65535;
  htim8.Init.ClockDivision = TIM_CLOCKDIVISION_DIV1;
  htim8.Init.RepetitionCounter = 0;
  htim8.Init.AutoReloadPreload = TIM_AUTORELOAD_PRELOAD_DISABLE;
  sConfig.EncoderMode = TIM_ENCODERMODE_TI1;
  sConfig.IC1Polarity = TIM_ICPOLARITY_RISING;
  sConfig.IC1Selection = TIM_ICSELECTION_DIRECTTI;
  sConfig.IC1Prescaler = TIM_ICPSC_DIV1;
  sConfig.IC1Filter = 0;
  sConfig.IC2Polarity = TIM_ICPOLARITY_RISING;
  sConfig.IC2Selection = TIM_ICSELECTION_DIRECTTI;
  sConfig.IC2Prescaler = TIM_ICPSC_DIV1;
  sConfig.IC2Filter = 0;
  if (HAL_TIM_Encoder_Init(&htim8, &sConfig) != HAL_OK)
  {
    Error_Handler();
  }
  sMasterConfig.MasterOutputTrigger = TIM_TRGO_RESET;
  sMasterConfig.MasterOutputTrigger2 = TIM_TRGO2_RESET;
  sMasterConfig.MasterSlaveMode = TIM_MASTERSLAVEMODE_DISABLE;
  if (HAL_TIMEx_MasterConfigSynchronization(&htim8, &sMasterConfig) != HAL_OK)
  {
    Error_Handler();
  }
  sEncoderIndexConfig.Polarity = TIM_ENCODERINDEX_POLARITY_NONINVERTED;
  sEncoderIndexConfig.Prescaler = TIM_ENCODERINDEX_PRESCALER_DIV1;
  sEncoderIndexConfig.Filter = 0;
  sEncoderIndexConfig.FirstIndexEnable = DISABLE;
  sEncoderIndexConfig.Position = TIM_ENCODERINDEX_POSITION_00;
  sEncoderIndexConfig.Direction = TIM_ENCODERINDEX_DIRECTION_UP_DOWN;
  if (HAL_TIMEx_ConfigEncoderIndex(&htim8, &sEncoderIndexConfig) != HAL_OK)
  {
    Error_Handler();
  }

}

static void MX_TIM15_Init(void)
{

  TIM_MasterConfigTypeDef sMasterConfig = {0};
  TIM_OC_InitTypeDef sConfigOC = {0};
  TIM_BreakDeadTimeConfigTypeDef sBreakDeadTimeConfig = {0};

  htim15.Instance = TIM15;
  htim15.Init.Prescaler = 0;
  htim15.Init.CounterMode = TIM_COUNTERMODE_UP;
  htim15.Init.Period = 65535;
  htim15.Init.ClockDivision = TIM_CLOCKDIVISION_DIV1;
  htim15.Init.RepetitionCounter = 0;
  htim15.Init.AutoReloadPreload = TIM_AUTORELOAD_PRELOAD_DISABLE;
  if (HAL_TIM_PWM_Init(&htim15) != HAL_OK)
  {
    Error_Handler();
  }
  sMasterConfig.MasterOutputTrigger = TIM_TRGO_RESET;
  sMasterConfig.MasterSlaveMode = TIM_MASTERSLAVEMODE_DISABLE;
  if (HAL_TIMEx_MasterConfigSynchronization(&htim15, &sMasterConfig) != HAL_OK)
  {
    Error_Handler();
  }
  sConfigOC.OCMode = TIM_OCMODE_PWM1;
  sConfigOC.Pulse = 0;
  sConfigOC.OCPolarity = TIM_OCPOLARITY_HIGH;
  sConfigOC.OCNPolarity = TIM_OCNPOLARITY_HIGH;
  sConfigOC.OCFastMode = TIM_OCFAST_DISABLE;
  sConfigOC.OCIdleState = TIM_OCIDLESTATE_RESET;
  sConfigOC.OCNIdleState = TIM_OCNIDLESTATE_RESET;
  if (HAL_TIM_PWM_ConfigChannel(&htim15, &sConfigOC, TIM_CHANNEL_2) != HAL_OK)
  {
    Error_Handler();
  }
  sBreakDeadTimeConfig.OffStateRunMode = TIM_OSSR_DISABLE;
  sBreakDeadTimeConfig.OffStateIDLEMode = TIM_OSSI_DISABLE;
  sBreakDeadTimeConfig.LockLevel = TIM_LOCKLEVEL_OFF;
  sBreakDeadTimeConfig.DeadTime = 0;
  sBreakDeadTimeConfig.BreakState = TIM_BREAK_DISABLE;
  sBreakDeadTimeConfig.BreakPolarity = TIM_BREAKPOLARITY_HIGH;
  sBreakDeadTimeConfig.BreakFilter = 0;
  sBreakDeadTimeConfig.AutomaticOutput = TIM_AUTOMATICOUTPUT_DISABLE;
  if (HAL_TIMEx_ConfigBreakDeadTime(&htim15, &sBreakDeadTimeConfig) != HAL_OK)
  {
    Error_Handler();
  }
  HAL_TIM_MspPostInit(&htim15);

}

static void MX_TIM16_Init(void)
{

  TIM_OC_InitTypeDef sConfigOC = {0};
  TIM_BreakDeadTimeConfigTypeDef sBreakDeadTimeConfig = {0};

  htim16.Instance = TIM16;
  htim16.Init.Prescaler = 0;
  htim16.Init.CounterMode = TIM_COUNTERMODE_UP;
  htim16.Init.Period = 65535;
  htim16.Init.ClockDivision = TIM_CLOCKDIVISION_DIV1;
  htim16.Init.RepetitionCounter = 0;
  htim16.Init.AutoReloadPreload = TIM_AUTORELOAD_PRELOAD_DISABLE;
  if (HAL_TIM_Base_Init(&htim16) != HAL_OK)
  {
    Error_Handler();
  }
  if (HAL_TIM_PWM_Init(&htim16) != HAL_OK)
  {
    Error_Handler();
  }
  sConfigOC.OCMode = TIM_OCMODE_PWM1;
  sConfigOC.Pulse = 0;
  sConfigOC.OCPolarity = TIM_OCPOLARITY_HIGH;
  sConfigOC.OCNPolarity = TIM_OCNPOLARITY_HIGH;
  sConfigOC.OCFastMode = TIM_OCFAST_DISABLE;
  sConfigOC.OCIdleState = TIM_OCIDLESTATE_RESET;
  sConfigOC.OCNIdleState = TIM_OCNIDLESTATE_RESET;
  if (HAL_TIM_PWM_ConfigChannel(&htim16, &sConfigOC, TIM_CHANNEL_1) != HAL_OK)
  {
    Error_Handler();
  }
  sBreakDeadTimeConfig.OffStateRunMode = TIM_OSSR_DISABLE;
  sBreakDeadTimeConfig.OffStateIDLEMode = TIM_OSSI_DISABLE;
  sBreakDeadTimeConfig.LockLevel = TIM_LOCKLEVEL_OFF;
  sBreakDeadTimeConfig.DeadTime = 0;
  sBreakDeadTimeConfig.BreakState = TIM_BREAK_DISABLE;
  sBreakDeadTimeConfig.BreakPolarity = TIM_BREAKPOLARITY_HIGH;
  sBreakDeadTimeConfig.BreakFilter = 0;
  sBreakDeadTimeConfig.AutomaticOutput = TIM_AUTOMATICOUTPUT_DISABLE;
  if (HAL_TIMEx_ConfigBreakDeadTime(&htim16, &sBreakDeadTimeConfig) != HAL_OK)
  {
    Error_Handler();
  }

}

static void MX_TIM17_Init(void)
{

  TIM_OC_InitTypeDef sConfigOC = {0};
  TIM_BreakDeadTimeConfigTypeDef sBreakDeadTimeConfig = {0};

  htim17.Instance = TIM17;
  htim17.Init.Prescaler = 0;
  htim17.Init.CounterMode = TIM_COUNTERMODE_UP;
  htim17.Init.Period = 65535;
  htim17.Init.ClockDivision = TIM_CLOCKDIVISION_DIV1;
  htim17.Init.RepetitionCounter = 0;
  htim17.Init.AutoReloadPreload = TIM_AUTORELOAD_PRELOAD_DISABLE;
  if (HAL_TIM_Base_Init(&htim17) != HAL_OK)
  {
    Error_Handler();
  }
  if (HAL_TIM_PWM_Init(&htim17) != HAL_OK)
  {
    Error_Handler();
  }
  sConfigOC.OCMode = TIM_OCMODE_PWM1;
  sConfigOC.Pulse = 0;
  sConfigOC.OCPolarity = TIM_OCPOLARITY_HIGH;
  sConfigOC.OCNPolarity = TIM_OCNPOLARITY_HIGH;
  sConfigOC.OCFastMode = TIM_OCFAST_DISABLE;
  sConfigOC.OCIdleState = TIM_OCIDLESTATE_RESET;
  sConfigOC.OCNIdleState = TIM_OCNIDLESTATE_RESET;
  if (HAL_TIM_PWM_ConfigChannel(&htim17, &sConfigOC, TIM_CHANNEL_1) != HAL_OK)
  {
    Error_Handler();
  }
  sBreakDeadTimeConfig.OffStateRunMode = TIM_OSSR_DISABLE;
  sBreakDeadTimeConfig.OffStateIDLEMode = TIM_OSSI_DISABLE;
  sBreakDeadTimeConfig.LockLevel = TIM_LOCKLEVEL_OFF;
  sBreakDeadTimeConfig.DeadTime = 0;
  sBreakDeadTimeConfig.BreakState = TIM_BREAK_DISABLE;
  sBreakDeadTimeConfig.BreakPolarity = TIM_BREAKPOLARITY_HIGH;
  sBreakDeadTimeConfig.BreakFilter = 0;
  sBreakDeadTimeConfig.AutomaticOutput = TIM_AUTOMATICOUTPUT_DISABLE;
  if (HAL_TIMEx_ConfigBreakDeadTime(&htim17, &sBreakDeadTimeConfig) != HAL_OK)
  {
    Error_Handler();
  }

}

static void MX_UART5_Init(void)
{

  huart5.Instance = UART5;
  huart5.Init.BaudRate = 115200;
  huart5.Init.WordLength = UART_WORDLENGTH_8B;
  huart5.Init.StopBits = UART_STOPBITS_1;
  huart5.Init.Parity = UART_PARITY_NONE;
  huart5.Init.Mode = UART_MODE_TX_RX;
  huart5.Init.HwFlowCtl = UART_HWCONTROL_NONE;
  huart5.Init.OverSampling = UART_OVERSAMPLING_16;
  huart5.Init.OneBitSampling = UART_ONE_BIT_SAMPLE_DISABLE;
  huart5.Init.ClockPrescaler = UART_PRESCALER_DIV1;
  huart5.AdvancedInit.AdvFeatureInit = UART_ADVFEATURE_NO_INIT;
  if (HAL_UART_Init(&huart5) != HAL_OK)
  {
    Error_Handler();
  }
  if (HAL_UARTEx_SetTxFifoThreshold(&huart5, UART_TXFIFO_THRESHOLD_1_8) != HAL_OK)
  {
    Error_Handler();
  }
  if (HAL_UARTEx_SetRxFifoThreshold(&huart5, UART_RXFIFO_THRESHOLD_1_8) != HAL_OK)
  {
    Error_Handler();
  }
  if (HAL_UARTEx_DisableFifoMode(&huart5) != HAL_OK)
  {
    Error_Handler();
  }

}

static void MX_USART3_UART_Init(void)
{

  huart3.Instance = USART3;
  huart3.Init.BaudRate = 921600;
  huart3.Init.WordLength = UART_WORDLENGTH_8B;
  huart3.Init.StopBits = UART_STOPBITS_1;
  huart3.Init.Parity = UART_PARITY_NONE;
  huart3.Init.Mode = UART_MODE_TX_RX;
  huart3.Init.HwFlowCtl = UART_HWCONTROL_NONE;
  huart3.Init.OverSampling = UART_OVERSAMPLING_16;
  huart3.Init.OneBitSampling = UART_ONE_BIT_SAMPLE_DISABLE;
  huart3.Init.ClockPrescaler = UART_PRESCALER_DIV1;
  huart3.AdvancedInit.AdvFeatureInit = UART_ADVFEATURE_NO_INIT;
  if (HAL_UART_Init(&huart3) != HAL_OK)
  {
    Error_Handler();
  }
  if (HAL_UARTEx_SetTxFifoThreshold(&huart3, UART_TXFIFO_THRESHOLD_1_8) != HAL_OK)
  {
    Error_Handler();
  }
  if (HAL_UARTEx_SetRxFifoThreshold(&huart3, UART_RXFIFO_THRESHOLD_1_8) != HAL_OK)
  {
    Error_Handler();
  }
  if (HAL_UARTEx_DisableFifoMode(&huart3) != HAL_OK)
  {
    Error_Handler();
  }

}

static void MX_DMA_Init(void)
{

  /* DMA controller clock enable */
  __HAL_RCC_DMAMUX1_CLK_ENABLE();
  __HAL_RCC_DMA1_CLK_ENABLE();

  /* DMA interrupt init */
  /* DMA1_Channel1_IRQn interrupt configuration */
  HAL_NVIC_SetPriority(DMA1_Channel1_IRQn, 5, 0);
  HAL_NVIC_EnableIRQ(DMA1_Channel1_IRQn);
  /* DMA1_Channel2_IRQn interrupt configuration */
  HAL_NVIC_SetPriority(DMA1_Channel2_IRQn, 5, 0);
  HAL_NVIC_EnableIRQ(DMA1_Channel2_IRQn);

}

static void MX_GPIO_Init(void)
{
  GPIO_InitTypeDef GPIO_InitStruct = {0};

  /* GPIO Ports Clock Enable */
  __HAL_RCC_GPIOC_CLK_ENABLE();
  __HAL_RCC_GPIOF_CLK_ENABLE();
  __HAL_RCC_GPIOA_CLK_ENABLE();
  __HAL_RCC_GPIOB_CLK_ENABLE();
  __HAL_RCC_GPIOD_CLK_ENABLE();

  /*Configure GPIO pin Output Level */
  HAL_GPIO_WritePin(GPIOC, STAT_BKUP_Pin|EN_5V_Pin|CAM1_CTRL_Pin, GPIO_PIN_RESET);

  /*Configure GPIO pin Output Level */
  HAL_GPIO_WritePin(GPIOA, DRV_DIR_Pin|CAM0_CTRL_Pin|XBEE_RST_Pin, GPIO_PIN_RESET);

  /*Configure GPIO pin Output Level */
  HAL_GPIO_WritePin(GPIOB, IMU_nCS_Pin|MAGEXT_nCS_Pin|MAG_nCS_Pin|BMP_nCS_Pin
                          |GPS_RST_Pin|USR_LED_Pin, GPIO_PIN_RESET);

  /*Configure GPIO pins : STAT_BKUP_Pin EN_5V_Pin CAM1_CTRL_Pin */
  GPIO_InitStruct.Pin = STAT_BKUP_Pin|EN_5V_Pin|CAM1_CTRL_Pin;
  GPIO_InitStruct.Mode = GPIO_MODE_OUTPUT_PP;
  GPIO_InitStruct.Pull = GPIO_NOPULL;
  GPIO_InitStruct.Speed = GPIO_SPEED_FREQ_LOW;
  HAL_GPIO_Init(GPIOC, &GPIO_InitStruct);

  /*Configure GPIO pins : CHG_STAT2_Pin CHG_STAT1_Pin */
  GPIO_InitStruct.Pin = CHG_STAT2_Pin|CHG_STAT1_Pin;
  GPIO_InitStruct.Mode = GPIO_MODE_INPUT;
  GPIO_InitStruct.Pull = GPIO_NOPULL;
  HAL_GPIO_Init(GPIOF, &GPIO_InitStruct);

  /*Configure GPIO pin : CLK_32K_Pin */
  GPIO_InitStruct.Pin = CLK_32K_Pin;
  GPIO_InitStruct.Mode = GPIO_MODE_ANALOG;
  GPIO_InitStruct.Pull = GPIO_NOPULL;
  HAL_GPIO_Init(CLK_32K_GPIO_Port, &GPIO_InitStruct);

  /*Configure GPIO pins : DRV_DIR_Pin CAM0_CTRL_Pin XBEE_RST_Pin */
  GPIO_InitStruct.Pin = DRV_DIR_Pin|CAM0_CTRL_Pin|XBEE_RST_Pin;
  GPIO_InitStruct.Mode = GPIO_MODE_OUTPUT_PP;
  GPIO_InitStruct.Pull = GPIO_NOPULL;
  GPIO_InitStruct.Speed = GPIO_SPEED_FREQ_LOW;
  HAL_GPIO_Init(GPIOA, &GPIO_InitStruct);

  /*Configure GPIO pins : IMU_nCS_Pin MAGEXT_nCS_Pin MAG_nCS_Pin BMP_nCS_Pin
                           USR_LED_Pin */
  GPIO_InitStruct.Pin = IMU_nCS_Pin|MAGEXT_nCS_Pin|MAG_nCS_Pin|BMP_nCS_Pin
                          |USR_LED_Pin;
  GPIO_InitStruct.Mode = GPIO_MODE_OUTPUT_PP;
  GPIO_InitStruct.Pull = GPIO_NOPULL;
  GPIO_InitStruct.Speed = GPIO_SPEED_FREQ_LOW;
  HAL_GPIO_Init(GPIOB, &GPIO_InitStruct);

  /*Configure GPIO pin : PA8 */
  GPIO_InitStruct.Pin = GPIO_PIN_8;
  GPIO_InitStruct.Mode = GPIO_MODE_AF_PP;
  GPIO_InitStruct.Pull = GPIO_NOPULL;
  GPIO_InitStruct.Speed = GPIO_SPEED_FREQ_LOW;
  GPIO_InitStruct.Alternate = GPIO_AF0_MCO;
  HAL_GPIO_Init(GPIOA, &GPIO_InitStruct);

  /*Configure GPIO pins : PB4 PB6 */
  GPIO_InitStruct.Pin = GPIO_PIN_4|GPIO_PIN_6;
  GPIO_InitStruct.Mode = GPIO_MODE_ANALOG;
  GPIO_InitStruct.Pull = GPIO_NOPULL;
  HAL_GPIO_Init(GPIOB, &GPIO_InitStruct);

  /*Configure GPIO pin : GPS_RST_Pin */
  GPIO_InitStruct.Pin = GPS_RST_Pin;
  GPIO_InitStruct.Mode = GPIO_MODE_OUTPUT_OD;
  GPIO_InitStruct.Pull = GPIO_NOPULL;
  GPIO_InitStruct.Speed = GPIO_SPEED_FREQ_LOW;
  HAL_GPIO_Init(GPS_RST_GPIO_Port, &GPIO_InitStruct);

  /*Configure GPIO pin : BUZZER_Pin */
  GPIO_InitStruct.Pin = BUZZER_Pin;
  GPIO_InitStruct.Mode = GPIO_MODE_AF_PP;
  GPIO_InitStruct.Pull = GPIO_NOPULL;
  GPIO_InitStruct.Speed = GPIO_SPEED_FREQ_LOW;
  GPIO_InitStruct.Alternate = GPIO_AF6_IR;
  HAL_GPIO_Init(BUZZER_GPIO_Port, &GPIO_InitStruct);

  /**/
  __HAL_SYSCFG_FASTMODEPLUS_ENABLE(SYSCFG_FASTMODEPLUS_PB9);

}

/* USER CODE BEGIN 4 */

/* ------------------------------------------------------------------------------------------------------------------------------------------------------- */
/*                                 This code block is to be used for any helper functions for anything other than a driver                                 */
/* ------------------------------------------------------------------------------------------------------------------------------------------------------- */

// Parse a time string in format HH:MM:SS into uint32 milliseconds
// This is technically a 24 hour format conversion
uint32_t parse_str_time_ms(const char *s) {
    if (!s || s[0] == '\0')
        return 0;

    // hh
    uint32_t hours =
        (s[0] - '0') * 10 +
        (s[1] - '0');
    // Skip ':' at s[2]
    // mm
    uint32_t minutes =
        (s[3] - '0') * 10 +
        (s[4] - '0');
    // Skip ':' at s[5]
    // ss
    uint32_t seconds =
        (s[6] - '0') * 10 +
        (s[7] - '0');

    return
        hours   * 3600000UL +
        minutes * 60000UL +
        seconds * 1000UL;
}

// Idea is to calculateAltitude then immediately call this function to detemrine state.
void determineState(double altitude){
    // LAUNCH_PAD state
    if (strcmp(global_mission_data.STATE, "LAUNCH_PAD") == 0)
    {
        if (altitude > launch_altitude_threshold) {
            char _state[] = "ASCENT";
            memcpy(global_mission_data.STATE, _state, sizeof(_state));
        }
    }
    else if (strcmp(global_mission_data.STATE, "ASCENT") == 0)
    {
        if (altitude > max_altitude)
        	max_altitude = altitude;

        if (fmax(fmax(altitude_history[0], altitude_history[1]), altitude_history[2]) == altitude_history[0]) {
            mec_wire_enable = 1;

            char _state[] = "APOGEE";
            memcpy(global_mission_data.STATE, _state, sizeof(_state));
        }
    }
    else if (strcmp(global_mission_data.STATE, "APOGEE") == 0)
    {
    	char _state[] = "DESCENT";
    	memcpy(global_mission_data.STATE, _state, sizeof(_state));
    }
    else if (strcmp(global_mission_data.STATE, "DESCENT") == 0)
    {
    	if (altitude < (max_altitude * release_height_percentage)) {
    		char _state = "PROBE_RELEASE";
    	}
    }
    else if (strcmp(global_mission_data.STATE, "PROBE_RELEASE") == 0)
    {
    	if (altitude <= egg_drop_height) {
			drop_egg_enable = 1;
			char _state[] = "PAYLOAD_RELEASE";
			memcpy(global_mission_data.STATE, _state, sizeof(_state));
		}
    }
    else if (strcmp(global_mission_data.STATE, "PAYLOAD_RELEASE") == 0)
    {
    	char _state[] = "LANDED";
    	memcpy(global_mission_data.STATE, _state, sizeof(_state));
    }
}

void send_api_frame(uint8_t *payload, uint16_t payload_len, uint8_t frame_id)
{
    uint8_t frame[128];
    uint16_t i = 0;

    // Start delimiter
    frame[i++] = 0x7E;

    // Length placeholder
    frame[i++] = 0x00;
    frame[i++] = 0x00;

    uint16_t start = i;

    // Frame type
    frame[i++] = 0x10;

    // Frame ID
    frame[i++] = frame_id;

    // 64-bit dest (broadcast)
    frame[i++] = 0x00;
    frame[i++] = 0x00;
    frame[i++] = 0x00;
    frame[i++] = 0x00;
    frame[i++] = 0x00;
    frame[i++] = 0x00;
    frame[i++] = 0xFF;
    frame[i++] = 0xFF;

    // 16-bit addr
    frame[i++] = 0xFF;
    frame[i++] = 0xFE;

    // Radius + options
    frame[i++] = 0x00;
    frame[i++] = 0x00;

    // Payload
    memcpy(&frame[i], payload, payload_len);
    i += payload_len;

    // Length
    uint16_t length = i - start;
    frame[1] = (length >> 8) & 0xFF;
    frame[2] = length & 0xFF;

    // Checksum
    uint8_t sum = 0;
    for (uint16_t j = start; j < i; j++)
        sum += frame[j];

    frame[i++] = 0xFF - sum;

    HAL_UART_Transmit(&huart3, frame, i, HAL_MAX_DELAY);
}

void send_packet(uint8_t *data, uint16_t len)
{
    uint16_t offset = 0;
    uint8_t frame_id = 1;

    while (offset < len)
    {
        uint16_t chunk_len = len - offset;

        if (chunk_len > XBEE_MAX_PAYLOAD)
            chunk_len = XBEE_MAX_PAYLOAD;

        send_api_frame(&data[offset], chunk_len, 0);

        offset += chunk_len;
    }
}

/* -------------------------------------------------------------------------------------------------------------------------------------------------------- */
/*                                                                 START THREAD DEFINITIONS                                                                 */
/* -------------------------------------------------------------------------------------------------------------------------------------------------------- */
/* USER CODE END 4 */

void StartReadSensors(void const * argument)
{
  /* init code for USB_Device */
  MX_USB_Device_Init();
  /* USER CODE BEGIN 5 */
  volatile MS5607Readings bmp_data;      // pressure data
  volatile ICM42688P_AccelData imu_data; // accelerometer / gyro data
  volatile BMM150_mag_data mag_data;     // DELETE: magnetometer data (unused)

  // Holds the number of quadrature encoder revolutions measured in the
  // previous and current telemetry packet, respectively (used to calculate
  // auto-gyro rotation rate)
  volatile int16_t prev_enc_count = 0;
  volatile int16_t enc_count = 0;

  osStatus stat = osErrorOS;
  GGA_Data_t gps_data;

  volatile uint8_t gps_array_check[83] = {0};

  /* Infinite loop */
  for(;;)
  {
//	  HAL_UART_Transmit(&huart3, gps_data.sats, 3, HAL_MAX_DELAY);
	  // read quadrature encoder values
	  enc_count = QENC_Get_Encoder0_Count();

	  stat = osSemaphoreWait(globalDataHandle, 100);
	  if (stat != osOK) {
		  osThreadYield();
		  continue;
	  }

	  bmp_data = MS5607ReadValues();

	  // record sensor data into the global mission data struct
	  global_mission_data.TEMPERATURE = bmp_data.temperature_C;

	  // in simulation mode, update pressure to match what is parsed from command
	  if (simulation_enable == 1)
	  {
		global_mission_data.PRESSURE = simulated_pressure;
		global_mission_data.MODE = 'S'; // set mode to 'S' for simulation
	  }
	  // otherwise, update pressure to match data read from sensor
	  else
	  {
		global_mission_data.PRESSURE = bmp_data.pressure_kPa;
		global_mission_data.MODE = 'F'; // set mode to 'F' for flight
	  }
	  // if the calibrating flag is true, calibrate the altitude
	  global_mission_data.ALTITUDE = calculateAltitude(global_mission_data.PRESSURE);
	  if (is_calibrated == 1)
	  {
		global_mission_data.ALTITUDE_OFFSET = global_mission_data.ALTITUDE; // set the offset to the current altitude
		is_calibrated = 0;                                                  // reset the flag
	  }
	  // Use altitude to update the mission state as needed
	  determineState(global_mission_data.ALTITUDE);

	  // update battery voltage
	  uint16_t battery_mV = 0;                                    // temp variable to hold the battery voltage in millivolts
	  BQ28Z610_ReadVoltage(&hi2c3, &battery_mV);                  // read battery voltage from BQZ
	  global_mission_data.VOLTAGE = (float)(battery_mV) / 1000.0; // convert from mV to V

	  imu_data = ICM42688P_read_data();
	  // read gyro data
	  global_mission_data.GYRO_R = imu_data.gyro_y;
	  global_mission_data.GYRO_P = imu_data.gyro_x;
	  global_mission_data.GYRO_Y = imu_data.gyro_z;

	  // calculates the auto gyro rotation rate in degrees per second according to:
	  // (current count) - (previous count) * (360 degrees / 1 revolution) * (1 revolution / 120 counts)
	  global_mission_data.AUTO_GYRO_ROTATION_RATE = (enc_count - prev_enc_count) * 3;

	  // read gyro acceleration data
	  // FIXME : IMU data is currently raw values, not angular rates
	  global_mission_data.ACCEL_R = imu_data.accel_y;
	  global_mission_data.ACCEL_P = imu_data.accel_x;
	  global_mission_data.ACCEL_Y = imu_data.accel_z;

	  // update magnetometer; dummy data
	  global_mission_data.MAG_R = rand() % 1000 / 1000.0; // mag_r
	  global_mission_data.MAG_P = rand() % 1000 / 1000.0; // mag_p
	  global_mission_data.MAG_Y = rand() % 1000 / 1000.0; // mag_y
	  /*
	  global_mission_data.MAG_R =  mag_data.x; // mag_r
	  global_mission_data.MAG_P = mag_data.y; // mag_p
	  global_mission_data.MAG_Y = mag_data.z; // mag_y
	  */

	  // This IF statement should be all that is needed to parse GPS data.
	  // Need to test though, apparently finding time to be outside to test it is harder than I thought.
	  if (GPS_READY) {
		  GPS_READY = 0;
		  char output[200] = { '\0' };
		  // The input should be a GNGGA message, but will be checked in parser function
		  // Parse the receive buffer for the GGA data.
//		  HAL_UART_Transmit(&huart3, receive_buffer, GPS_SIZE, HAL_MAX_DELAY);
		  int ret = parse_gga(&receive_buffer, &gps_data);
		  time_to_string(gps_data.time_ms, &gps_data.gps_time);

		  // Now copy data into the global_data struct.
		  global_mission_data.GPS_ALTITUDE = gps_data.altitude;
		  global_mission_data.GPS_LATITUDE = gps_data.latitude;
		  global_mission_data.GPS_LONGITUDE = gps_data.longitude;
		  global_mission_data.GPS_SATS = gps_data.num_satellites;
		  strcpy(global_mission_data.GPS_TIME, gps_data.gps_time);
//		  HAL_UART_Transmit(&huart3, receive_buffer, GPS_SIZE, HAL_MAX_DELAY);
		  memset(receive_buffer, 0, sizeof(receive_buffer));
	  }
	  if (gps_time_enable) {
		  global_mission_data.MISSION_TIME = gps_data.time_ms;
		  gps_time_enable = 0; // It is only *set* by the GPS or by default in global.c
	  }

	  osSemaphoreRelease(globalDataHandle);
	  osThreadYield();
  } // END FOR LOOP

  // Should never leave loop, but just in case
  osThreadTerminate(NULL);
  /* USER CODE END 5 */
}

void StartSendTelemetry(void const * argument)
{
  /* USER CODE BEGIN StartSendTelemetry */
	osStatus stat = osErrorOS;
  /* Infinite loop */
  for(;;)
  {
	  if (telemetry_enable)
	  {
		HAL_GPIO_WritePin(USR_LED_GPIO_Port, USR_LED_Pin, GPIO_PIN_RESET);
		osDelay(100);
		HAL_GPIO_WritePin(USR_LED_GPIO_Port, USR_LED_Pin, GPIO_PIN_SET);
//		HAL_GPIO_TogglePin(USR_LED_GPIO_Port, USR_LED_Pin);
//		  HAL_GPIO_WritePin(USR_LED_GPIO_Port, USR_LED_Pin, GPIO_PIN_RESET);
		stat = osSemaphoreWait(globalDataHandle, 100);
		if (stat != osOK) {
			osThreadYield();
			continue;
		}

//	    HAL_GPIO_WritePin(USR_LED_GPIO_Port, USR_LED_Pin, GPIO_PIN_SET);
		// create an empty buffer for the telemetry packet string
		char telemetry_string[200];
		uint16_t str_len = 0;

		// Convert mission time from milliseconds to a string format
		char mission_time[8];
		time_to_string(global_mission_data.MISSION_TIME, &mission_time);

		// Test new GCS:
		// "TEAM_ID","MISSION_TIME","PACKET_COUNT","MODE","STATE","ALTITUDE", "TEMPERATURE", "PRESSURE", "VOLTAGE","CURRENT",
        // "GYRO_R", "GYRO_P", "GYRO_Y", "ACCEL_R", "ACCEL_P", "ACCEL_Y", "GPS_TIME", "GPS_ALTITUDE",
		// "GPS_LATITUDE", "GPS_LONGITUDE", "GPS_SATS", "CMD_ECHO"
//		str_len = sprintf(telemetry_string, "%d,%s,%ld,%c,%s,%3.1f,%.1f,%.1f,%.1f,%.1f,%d,%d,%d,%d,%d,%d,%s,%.1f,%.4f,%.4f,%d,%s",
//				1075,
//				mission_time,
//				global_mission_data.PACKET_COUNT,
//				global_mission_data.MODE,
//				global_mission_data.STATE,
//				global_mission_data.ALTITUDE,
//				global_mission_data.TEMPERATURE,
//				global_mission_data.PRESSURE,
//				global_mission_data.VOLTAGE,
//				100.0,
//				global_mission_data.GYRO_R,
//				global_mission_data.GYRO_P,
//				global_mission_data.GYRO_Y,
//				global_mission_data.ACCEL_R,
//				global_mission_data.ACCEL_P,
//				global_mission_data.ACCEL_Y,
//				global_mission_data.GPS_TIME,
//				global_mission_data.GPS_ALTITUDE,
//				global_mission_data.GPS_LATITUDE,
//				global_mission_data.GPS_LONGITUDE,
//				global_mission_data.GPS_SATS,
//				global_mission_data.CMD_ECHO);

		// fill the buffer with the formatted packet data
		str_len = sprintf(telemetry_string, "%d,%s,%ld,%c,%s,%3.1f,%.1f,%.1f,%.1f,%.5f,%.5f,%.5f,%.5f,%.5f,%.5f,%.1f,%.1f,%.1f,%d,%s,%.1f,%.4f,%.4f,%d,%s",
						  global_mission_data.TEAM_ID,      			// team id (3174)
						  mission_time, 								// mission time converted to a string
						  global_mission_data.PACKET_COUNT, 			// packet count
						  global_mission_data.MODE,         			// mode
						  global_mission_data.STATE,        			// state
						  global_mission_data.ALTITUDE,     			// calibrated altitude (m)
						  global_mission_data.TEMPERATURE,  			// temperature (C)
						  global_mission_data.PRESSURE,     			// pressure (kPa)
						  global_mission_data.VOLTAGE,      			// battery voltage (V)
						  global_mission_data.GYRO_R,					// gyro roll (degrees/s)
						  global_mission_data.GYRO_P,					// gyro pitch (degrees/s)
						  global_mission_data.GYRO_Y,					// gyro yaw (degrees/s)
						  global_mission_data.ACCEL_R,					// accelerometer roll (degrees/s^2)
						  global_mission_data.ACCEL_P,					// accelerometer pitch (degrees/s^2)
						  global_mission_data.ACCEL_Y,					// accelerometer yaw (degrees/s^2)
						  global_mission_data.MAG_R,					// magnetometer roll
						  global_mission_data.MAG_P,					// magnetometer pitch
						  global_mission_data.MAG_Y,					// magnetometer yaw
						  global_mission_data.AUTO_GYRO_ROTATION_RATE,	// auto-gyro rotation rate (rps)
						  global_mission_data.GPS_TIME,					// GPS time
						  global_mission_data.GPS_ALTITUDE,				// GPS (absolute) altitude (m)
						  global_mission_data.GPS_LATITUDE,				// GPS latitude
						  global_mission_data.GPS_LONGITUDE,			// GPS longitude
						  global_mission_data.GPS_SATS,					// # of connected GPS satellites
						  global_mission_data.CMD_ECHO					// tracks previously received command
		);
		// Send the packet. The XBee will break this into 2 packets that need to be handled by the GCS
		// (in other words, the GCS will *have* to receive 2 packets and combine them)
//		send_packet((uint8_t*)telemetry_string, str_len);
		HAL_UART_Transmit(&huart3, telemetry_string, str_len, HAL_MAX_DELAY);

		/*char test_string[30];
		str_len = sprintf(test_string, "accel_z: %d", imu_data.accel_z);
		HAL_UART_Transmit(&huart3, test_string, str_len, HAL_MAX_DELAY);*/

		// increment packet count once the entire packet has been transmitted
		global_mission_data.PACKET_COUNT = global_mission_data.PACKET_COUNT + 1;
		// Since this is ~1/sec just add 1000 msec to mission time
		// This could be a uint16 and just store it in seconds, but there isn't much of advantage to that
		global_mission_data.MISSION_TIME = global_mission_data.MISSION_TIME + 1000;

		osSemaphoreRelease(globalDataHandle);

//		HAL_GPIO_WritePin(USR_LED_GPIO_Port, USR_LED_Pin, GPIO_PIN_RESET);
//		osDelay(100);
//		HAL_GPIO_WritePin(USR_LED_GPIO_Port, USR_LED_Pin, GPIO_PIN_SET);

		osDelay(1000);
	  } else {
		  HAL_GPIO_WritePin(USR_LED_GPIO_Port, USR_LED_Pin, GPIO_PIN_SET);
	  }
  } // END FOR LOOP

  // Should never leave loop, but just in case
    osThreadTerminate(NULL);

  /* USER CODE END StartSendTelemetry */
}

void StartReadCommands(void const * argument)
{
  /* USER CODE BEGIN StartReadCommands */
	osStatus stat = osErrorOS;
	volatile uint8_t update_time = 0;
  /* Infinite loop */
  for(;;)
  {
	  // receive command (22 bytes max)
	      // Now uses "command_buffer" from DMA
	  	  if (!COMMAND_READY) {
	  		  osThreadYield();
	  		  continue;
	  	  }

	      stat = osSemaphoreWait(globalDataHandle, 100);
		  if (stat != osOK) {
			  osThreadYield();
			  continue;
		  }

//	       HAL_UART_Transmit(&huart3, command_buffer, COMMAND_SIZE, HAL_MAX_DELAY);

	      // step1: convert rx_buff array of "uint8_t"s into array of "chars"
	      char rx_string[23];

	      // step2: convert array of chars into string  (https://www.geeksforgeeks.org/convert-character-array-to-string-in-c/)
	      strncpy(rx_string, command_buffer, 22);
	      memset(command_buffer, 0, BUFFER_SIZE);
	      COMMAND_READY = 0; // Done with the DMA buffer and can now signal a ready state for a new command.
	      // strcpy(global_mission_data.CMD_ECHO, rx_string);

	      // Add null terminator to end of command string
	      rx_string[22] = '\0';
	      // HAL_UART_Transmit(&huart3, rx_string, sizeof(rx_string), HAL_MAX_DELAY);

	      // CX ON command -> start transmitting telemetry packets
	      if (strncmp(rx_string, "CMD,3174,CX,ON", 14) == 0)
	      {
	        // set global telemetry flag
	        telemetry_enable = 1;

	        // set command echo in the global mission struct
	        char c_echo[] = "CXON";
	        strcpy(global_mission_data.CMD_ECHO, c_echo);
	      }
	      // CX OFF command -> stop transmitting telemetry packets
	      else if (strncmp(rx_string, "CMD,3174,CX,OFF", 15) == 0)
	      {
	        // reset global telemetry flag
	        telemetry_enable = 0;

	        // set command echo
	        char c_echo[] = "CXOFF";
	        strcpy(global_mission_data.CMD_ECHO, c_echo);
	      }
	      // ST command -> set mission time
	      else if (strncmp(rx_string, "CMD,3174,ST,", 12) == 0)
	      {
	        // parse the timestamp to set to
	        char arg[9];
	        char *time_str = rx_string + 12;
	        strncpy(arg, time_str, 9);

	        // if a manual timestamp has been input...
	        if (strlen(arg) == 8)
	        {
	            // set mission time
	        	global_mission_data.MISSION_TIME = parse_str_time_ms(time_str);
	        	// Time is stored as milliseconds and converted for data transmission
	        }
	        // read time from GPS
	        else if (strncmp(time_str, "GPS", 3))
	        {
	          gps_time_enable = 1;
	        }
	        else
	        {
	          // if the string is not 8 characters long, set it to "00:00:00"
	          global_mission_data.MISSION_TIME = 0;
	          gps_time_enable = 0;
	        }
	        // set command echo
	        char c_echo[] = "ST";
	        strcpy(global_mission_data.CMD_ECHO, c_echo);
	      }
	      // SIM ENABLE command -> allow simulation mode to be activated
	      else if (strncmp(rx_string, "CMD,3174,SIM,ENABLE", 19) == 0)
	      {
	        // set global flag
	        simulation_pre = 1;
	        // set command echo
	        char c_echo[] = "SIMENABLE";
	        strcpy(global_mission_data.CMD_ECHO, c_echo);
	      }
	      // SIM ACTIVATE command -> turn simulation mode on
	      else if (strncmp(rx_string, "CMD,3174,SIM,ACTIVATE", 21) == 0)
	      {
	        // check that simulation mode has been activated
	        if (simulation_pre == 1)
	        {
	          // set global simulation flag
	          simulation_enable = 1;
	          // make first simulated pressure value match actual value
	          simulated_pressure = global_mission_data.PRESSURE;
	          // set command echo
	          char c_echo[] = "SIMACT";
	          strcpy(global_mission_data.CMD_ECHO, c_echo);
	        }
	      }
	      // SIM DISABLE command -> turn simulation mode off
	      else if (strncmp(rx_string, "CMD,3174,SIM,DISABLE", 20) == 0)
	      {
	        // reset global flag
	        simulation_enable = 0;
	        // set command echo
	        char c_echo[] = "SIMDIS";
	        strcpy(global_mission_data.CMD_ECHO, c_echo);
	      }
	      // SIMP command -> add simulated pressure data
	      else if (strncmp(rx_string, "CMD,3174,SIMP,", 14) == 0)
	      {
	        // parse inputted pressure data
	        char *pressure_str = rx_string + 14;
	        char *str_end;
	        long pressure_pa = atof(rx_string + 14);
	        // if (str_end == pressure_str || *str_end != '\0')
	        // it wasn't a valid number
	        // set simulated pressure to parsed value
	        simulated_pressure = pressure_pa;

	        // set command echo
	        char c_echo[] = "SIMP";
	        strcpy(global_mission_data.CMD_ECHO, c_echo);
	      }
	      // CAL command -> calibrate altitude
	      else if (strncmp(rx_string, "CMD,3174,CAL", 12) == 0)
	      {
	        // set global flag
	        is_calibrated = 1;
	        // Reset altitude_history array
	        altitude_history[0] = 0.0;
	        altitude_history[1] = 0.0;
	        altitude_history[2] = 0.0;
	        // set command echo
	        char c_echo[] = "CAL";
	        strcpy(global_mission_data.CMD_ECHO, c_echo);
	      }
	      // MEC WIRE ON command -> actuate resistor-filament system
	      else if (strncmp(rx_string, "CMD,3174,MEC,WIRE,ON", 20) == 0)
	      {
	        // set global falg
	        mec_wire_enable = 1;
	        // set command echo
	        char c_echo[] = "MECON";
	        strcpy(global_mission_data.CMD_ECHO, c_echo);
	        // DELETE:
	        HAL_UART_Transmit(&huart3, c_echo, sizeof(c_echo), HAL_MAX_DELAY);
	      }
	      // MEC WIRE OFF command -> manually stop actuating resistor-filament system
	      else if (strncmp(rx_string, "CMD,3174,MEC,WIRE,OFF", 21) == 0)
	      {
	        // disable global flag
	        mec_wire_enable = 0;
	        // set command echo
	        char c_echo[] = "MECOFF";
	        strcpy(global_mission_data.CMD_ECHO, c_echo);
	      }
	      else if (strncmp(rx_string, "CMD,3174,COLD", 13) == 0) {
	    	  LC76G_cold_start();
	    	  HAL_GPIO_WritePin(USR_LED_GPIO_Port, USR_LED_Pin, GPIO_PIN_RESET);
	    	  osDelay(500);
	    	  HAL_GPIO_WritePin(USR_LED_GPIO_Port, USR_LED_Pin, GPIO_PIN_SET);
	      }
//	       FIXME : Probably don't need an ELSE statement
	      else
	      {
//	    	  send_packet(rx_string, 22);
	    	  // Probably don't want to keep this in final version, but good for testing
	    	  strcpy(global_mission_data.CMD_ECHO,"INVALID");
	      }
	      osSemaphoreRelease(globalDataHandle);
		  osThreadYield();
  } // END OF FOR LOOP

  // Should never leave loop, but just in case
    osThreadTerminate(NULL);

  /* USER CODE END StartReadCommands */
}

void StartGNC(void const * argument)
{
  /* USER CODE BEGIN StartGNC */
  /* Infinite loop */
  for(;;)
  {
	  // A lot of this code will be written by Tristan (in MATLAB probably) and we will just need to translate it.
	  // The basics as I understand it is that we will take a couple seconds after PROBE_RELEASE to stabilize
	  //   and calculate stuff like initial turn to make and what altitude to start making our move to drop
	  //   the egg.
	  // Once this is done we will have 2 control loops, Loiter and Egg Drop.
	  // Loiter is as it sounds, make hot laps above the drop zone while descending.
	  // Egg Drop will control the pathing into the drop zone and initiate egg release
	  osThreadYield();
  }

  // Should never leave loop, but just in case
  osThreadTerminate(NULL);

  /* USER CODE END StartGNC */
}

void HAL_TIM_PeriodElapsedCallback(TIM_HandleTypeDef *htim)
{
  if (htim->Instance == TIM6)
  {
    HAL_IncTick();
  }
}

void Error_Handler(void)
{
  __disable_irq();
  while (1)
  {
  }
}
